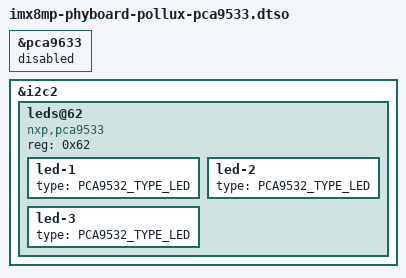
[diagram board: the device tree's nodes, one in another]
// SPDX-License-Identifier: (GPL-2.0-or-later OR MIT)
/*
 * Copyright (C) 2026 PHYTEC Messtechnik GmbH
 */

#include <dt-bindings/leds/leds-pca9532.h>

/dts-v1/;
/plugin/;

&pca9633 {
	status = "disabled";
};

&i2c2 {
	#address-cells = <1>;
	#size-cells = <0>;

	leds@62 {
		compatible = "nxp,pca9533";
		reg = <0x62>;

		led-1 {
			type = <PCA9532_TYPE_LED>;
		};

		led-2 {
			type = <PCA9532_TYPE_LED>;
		};

		led-3 {
			type = <PCA9532_TYPE_LED>;
		};
	};

};
